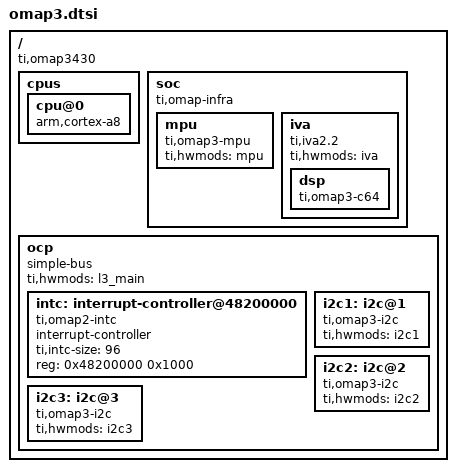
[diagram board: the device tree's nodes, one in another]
/*
 * Device Tree Source for OMAP3 SoC
 *
 * Copyright (C) 2011 Texas Instruments Incorporated - http://www.ti.com/
 *
 * This file is licensed under the terms of the GNU General Public License
 * version 2.  This program is licensed "as is" without any warranty of any
 * kind, whether express or implied.
 */

/include/ "skeleton.dtsi"

/ {
	compatible = "ti,omap3430", "ti,omap3";

	cpus {
		cpu@0 {
			compatible = "arm,cortex-a8";
		};
	};

	/*
	 * The soc node represents the soc top level view. It is uses for IPs
	 * that are not memory mapped in the MPU view or for the MPU itself.
	 */
	soc {
		compatible = "ti,omap-infra";
		mpu {
			compatible = "ti,omap3-mpu";
			ti,hwmods = "mpu";
		};

		iva {
			compatible = "ti,iva2.2";
			ti,hwmods = "iva";

			dsp {
				compatible = "ti,omap3-c64";
			};
		};
	};

	/*
	 * XXX: Use a flat representation of the OMAP3 interconnect.
	 * The real OMAP interconnect network is quite complex.
	 * Since that will not bring real advantage to represent that in DT for
	 * the moment, just use a fake OCP bus entry to represent the whole bus
	 * hierarchy.
	 */
	ocp {
		compatible = "simple-bus";
		#address-cells = <1>;
		#size-cells = <1>;
		ranges;
		ti,hwmods = "l3_main";

		intc: interrupt-controller@48200000 {
			compatible = "ti,omap2-intc";
			interrupt-controller;
			#interrupt-cells = <1>;
			ti,intc-size = <96>;
			reg = <0x48200000 0x1000>;
		};

		i2c1: i2c@1 {
			compatible = "ti,omap3-i2c";
			#address-cells = <1>;
			#size-cells = <0>;
			ti,hwmods = "i2c1";
		};

		i2c2: i2c@2 {
			compatible = "ti,omap3-i2c";
			#address-cells = <1>;
			#size-cells = <0>;
			ti,hwmods = "i2c2";
		};

		i2c3: i2c@3 {
			compatible = "ti,omap3-i2c";
			#address-cells = <1>;
			#size-cells = <0>;
			ti,hwmods = "i2c3";
		};
	};
};
